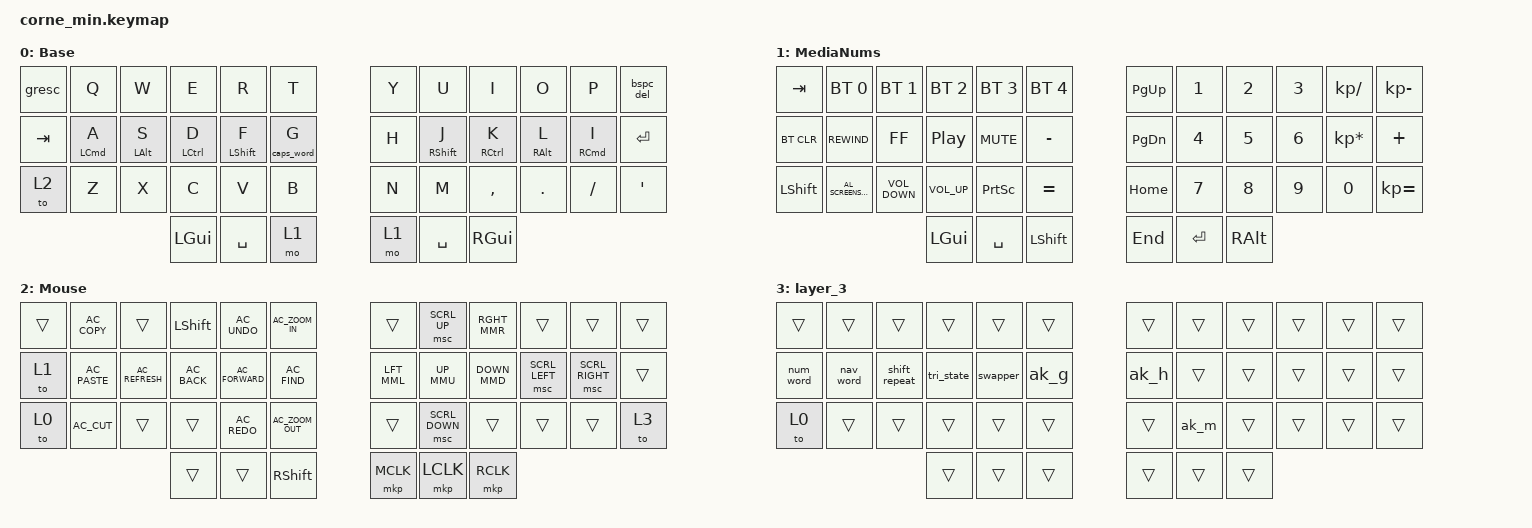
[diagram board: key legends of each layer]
/*
 * Copyright (c) 2020 The ZMK Contributors
 *
 * SPDX-License-Identifier: MIT
 */

#include <behaviors/num_word.dtsi>
#include <behaviors/unicode.dtsi>
#include <zmk-unicode/keys-extra.h>  // All glyphs except CJK
#include <zmk-unicode/keys-full.h>   // All glyphs including CJK
#include <behaviors.dtsi>
#include <dt-bindings/zmk/bt.h>
#include <dt-bindings/zmk/keys.h>
#include <dt-bindings/zmk/pointing.h>

#define DEAD1 F21
#define DEAD2 F22
#define DEAD3 F23
#define DEAD4 F24

/ {
    behaviors {
        bspc_del: bspc_del {
            compatible = "zmk,behavior-mod-morph";
            label = "BSPC_DEL";
            bindings = <&kp BSPC>, <&kp DELETE>;

            #binding-cells = <0>;
            mods = <(MOD_LSFT)>;
        };

        LFT_MML: LFT_MML {
            compatible = "zmk,behavior-mod-morph";
            label = "LFT_MML";
            bindings = <&kp LEFT_ARROW>, <&mmv MOVE_LEFT>;

            #binding-cells = <0>;
            mods = <(MOD_LSFT)>;
        };

        RGHT_MMR: RGHT_MMR {
            compatible = "zmk,behavior-mod-morph";
            label = "RGHT_MMR";
            bindings = <&kp RIGHT_ARROW>, <&mmv MOVE_RIGHT>;

            #binding-cells = <0>;
            mods = <(MOD_LSFT)>;
        };

        UP_MMU: UP_MMU {
            compatible = "zmk,behavior-mod-morph";
            label = "UP_MMU";
            bindings = <&kp UP_ARROW>, <&mmv MOVE_UP>;

            #binding-cells = <0>;
            mods = <(MOD_LSFT)>;
        };

        DOWN_MMD: DOWN_MMD {
            compatible = "zmk,behavior-mod-morph";
            label = "DOWN_MMD";
            bindings = <&kp DOWN_ARROW>, <&mmv MOVE_DOWN>;

            #binding-cells = <0>;
            mods = <(MOD_LSFT)>;
        };

        MAGIC_TAP: MAGIC_TAP {
            compatible = "zmk,behavior-hold-tap";
            label = "MAGIC_TAP";
            bindings = <&kp>, <&kp>;

            #binding-cells = <2>;
            tapping-term-ms = <350>;
            hold-trigger-on-release;
            flavor = "tap-preferred";
            quick-tap-ms = <350>;
            require-prior-idle-ms = <350>;
        };

        HMR_LEFT_TAP: HMR_LEFT_TAP {
            compatible = "zmk,behavior-hold-tap";
            label = "HMR_LEFT_TAP";
            bindings = <&kp>, <&kp>;

            #binding-cells = <2>;
            tapping-term-ms = <350>;
            quick-tap-ms = <350>;
            require-prior-idle-ms = <350>;
            hold-trigger-on-release;
            flavor = "tap-preferred";
            hold-trigger-key-positions = <6 7 8 9 10 11 18 19 20 21 22 23 30 31 32 33 34 35 39 40 41>;
        };

        HMR_RIGHT_TAP: HMR_RIGHT_TAP {
            compatible = "zmk,behavior-hold-tap";
            label = "HMR_RIGHT_TAP";
            bindings = <&kp>, <&kp>;

            #binding-cells = <2>;
            tapping-term-ms = <350>;
            quick-tap-ms = <350>;
            require-prior-idle-ms = <350>;
            hold-trigger-on-release;
            flavor = "tap-preferred";
            hold-trigger-key-positions = <0 1 2 3 4 5 12 13 14 15 16 17 24 25 26 27 28 29 36 37 38>;
        };

        MY_ALLCAPS: MY_ALLCAPS {
            compatible = "zmk,behavior-hold-tap";
            label = "MY_ALLCAPS";
            bindings = <&caps_word>, <&kp>;

            #binding-cells = <2>;
            tapping-term-ms = <350>;
            hold-trigger-on-release;
            flavor = "tap-preferred";
            quick-tap-ms = <350>;
            require-prior-idle-ms = <350>;
            hold-trigger-key-positions = <1 2 3 4 5 13 14 15 16 17 25 26 27 28 29 6 7 8 9 10 18 19 20 21 22 30 31>;
        };

        swapper: swapper {
            compatible = "zmk,behavior-tri-state";
            #binding-cells = <0>;
            bindings = <&kp A>, <&kp B>, <&kt C>;
        };

        tri_state: tri_state {
            compatible = "zmk,behavior-tri-state";
            label = "TRI-STATE";
            #binding-cells = <0>;
            bindings = <&kp A>, <&kp B>, <&kt C>;
        };

        //        leader1: leader1 {
        //            compatible = "zmk,behavior-leader-key";
        //            #binding-cells = <0>;
        //            
        //            ble { sequence = <B L E>; bindings = <&out OUT_BLE>; };
        //            bt0 { sequence = <B N0>; bindings = <&bt BT_SEL 0>; };
        //            bt1 { sequence = <B N1>; bindings = <&bt BT_SEL 1>; };
        //            bt2 { sequence = <B N2>; bindings = <&bt BT_SEL 2>; };
        //            btc { sequence = <C L E A R>; bindings = <&bt BT_CLR>; };
        //            boot { sequence = <B O O T>; bindings = <&bootloader>; };
        //            reset { sequence = <R E S E T>; bindings = <&sys_reset>; };
        //        };
        //
        //        leader2: leader2 {
        //            compatible = "zmk,behavior-leader-key";
        //            #binding-cells = <0>;
        //            
        //	    de_ae { sequence = <A E>; bindings = <&de_ae>; };
        //            de_oe { sequence = <O E>; bindings = <&de_oe>; };
        //            de_ue { sequence = <U E>; bindings = <&de_ue>; };
        //        };

        ak_h: ak_h {
            compatible = "zmk,behavior-adaptive-key";
            #binding-cells = <0>;
            bindings = <&kp H>;

            akt_ah {
                trigger-keys = <A>;
                max-prior-idle-ms = <300>;
                bindings = <&kp U>;
            };

            akt_uh {
                trigger-keys = <U>;
                max-prior-idle-ms = <300>;
                bindings = <&kp A>;
            };

            akt_eh {
                trigger-keys = <E>;
                max-prior-idle-ms = <300>;
                bindings = <&kp O>;
            };
        };

        ak_m: ak_m {
            compatible = "zmk,behavior-adaptive-key";
            #binding-cells = <0>;
            bindings = <&kp M>;

            akt_gm {
                trigger-keys = <G>;
                max-prior-idle-ms = <300>;
                bindings = <&kp L>;
            };

            akt_pm {
                trigger-keys = <P>;
                max-prior-idle-ms = <300>;
                bindings = <&kp L>;
            };
        };

        // And similarly for VP->VL, PV->LV, BT->BL, TB->LB

        ak_g: ak_g {
            compatible = "zmk,behavior-adaptive-key";
            #binding-cells = <0>;
            bindings = <&kp G>;

            // Binding two behaviors: JG->JPG

            akt_jg {
                trigger-keys = <J>;
                max-prior-idle-ms = <300>;
                bindings = <&kp P &kp G>;
            };
        };

        //        ak_e: ak_e {
        //            compatible = "zmk,behavior-adaptive-key";
        //            #binding-cells = <0>;
        //            bindings = <&kp E>;
        //            dead-keys = <GRAVE CARET APOS QUOTE>;
        //
        //            grave { trigger-keys = <GRAVE>; bindings = <&fr_e_grave>; };
        //            acute { trigger-keys = <APOS>; bindings = <&fr_e_acute>; };
        //            circumflex { trigger-keys = <CARET>; bindings = <&fr_e_circumflex>; };
        //            diaeresis { trigger-keys = <QUOTE>; bindings = <&fr_e_diaeresis>; };
        //        };

        shift_repeat: shift_repeat {
            compatible = "zmk,behavior-adaptive-key";
            #binding-cells = <0>;
            bindings = <&sk LSHFT>;

            repeat {
                trigger-keys = <A B C D E F G H I J K L M N O P Q R S T U V W X Y Z>;
                bindings = <&key_repeat>;
                max-prior-idle-ms = <350>;
                strict-modifiers;
            };
        };

        nav_word: nav_word {
            compatible = "zmk,behavior-auto-layer";
            #binding-cells = <1>;
            continue-list = <LEFT DOWN UP RIGHT PG_DN PG_UP>;
            ignore-modifiers;
        };

        num_word: num_word {
            #binding-cells = <0>;
            compatible = "zmk,behavior-num-word";
            continue-list = <BSPC DEL DOT COMMA PLUS MINUS STAR FSLH EQUAL>;
            ignore-numbers;
        };
    };

    combos { compatible = "zmk,combos"; };

    keymap {
        compatible = "zmk,keymap";

        Base_0 {
            display-name = "Base";

            // -----------------------------------------------------------------------------------------
            // |  TAB |  Q  |  W  |  E  |  R  |  T  |   |  Y  |  U   |  I  |  O  |  P  | BSPC |
            // | CTRL |  A  |  S  |  D  |  F  |  G  |   |  H  |  J   |  K  |  L  |  ;  |  '   |
            // | SHFT |  Z  |  X  |  C  |  V  |  B  |   |  N  |  M   |  ,  |  .  |  /  | ESC  |
            //                    | GUI | LWR | SPC |   | ENT | RSE  | ALT |

            bindings = <
&gresc   &kp Q                 &kp W                     &kp E                         &kp R                       &kp T              &kp Y  &kp U                         &kp I                   &kp O                  &kp P                  &bspc_del
&kp TAB  &HMR_LEFT_TAP LCMD A  &HMR_LEFT_TAP LEFT_ALT S  &HMR_LEFT_TAP LEFT_CONTROL D  &HMR_LEFT_TAP LEFT_SHIFT F  &MY_ALLCAPS 0 G    &kp H  &HMR_RIGHT_TAP RIGHT_SHIFT J  &HMR_RIGHT_TAP RCTRL K  &HMR_RIGHT_TAP RALT L  &HMR_RIGHT_TAP RCMD I  &kp RET
&to 2    &kp Z                 &kp X                     &kp C                         &kp V                       &kp B              &kp N  &kp M                         &kp COMMA               &kp DOT                &kp FSLH               &kp SQT
                                                         &kp LEFT_GUI                  &kp SPACE                   &mo 1              &mo 1  &kp SPACE                     &kp RIGHT_GUI
            >;
        };

        MediaNums {
            display-name = "MediaNums";

            // -----------------------------------------------------------------------------------------
            // |  TAB |  1  |  2  |  3  |  4  |  5  |   |  6  |  7  |  8  |  9  |  0  | BSPC |
            // | BTCLR| BT1 | BT2 | BT3 | BT4 | BT5 |   | LFT | DWN |  UP | RGT |     |      |
            // | SHFT |     |     |     |     |     |   |     |     |     |     |     |      |
            //                    | GUI |     | SPC |   | ENT |     | ALT |

            bindings = <
&kp TAB     &bt BT_SEL 0          &bt BT_SEL 1       &bt BT_SEL 2      &bt BT_SEL 3     &bt BT_SEL 4    &kp PG_UP      &kp NUMBER_1  &kp NUMBER_2  &kp NUMBER_3  &kp KP_DIVIDE    &kp KP_SUBTRACT
&bt BT_CLR  &kp C_REWIND          &kp C_FF           &kp C_PLAY_PAUSE  &kp C_MUTE       &kp MINUS       &kp PAGE_DOWN  &kp NUMBER_4  &kp N5        &kp NUMBER_6  &kp KP_MULTIPLY  &kp PLUS
&kp LSHFT   &kp C_AL_SCREENSAVER  &kp C_VOLUME_DOWN  &kp C_VOLUME_UP   &kp PRINTSCREEN  &kp EQUAL       &kp HOME       &kp N7        &kp N8        &kp N9        &kp N0           &kp KP_EQUAL
                                                     &kp LGUI          &kp SPACE        &kp LSHFT       &kp END        &kp RET       &kp RALT
            >;

            label = "MediaNums";
        };

        Mouse {
            bindings = <
&trans  &kp C_AC_COPY   &trans            &kp LSHFT      &kp C_AC_UNDO     &kp C_AC_ZOOM_IN     &trans     &msc SCRL_UP    &RGHT_MMR  &trans          &trans           &trans
&to 1   &kp C_AC_PASTE  &kp C_AC_REFRESH  &kp C_AC_BACK  &kp C_AC_FORWARD  &kp C_AC_FIND        &LFT_MML   &UP_MMU         &DOWN_MMD  &msc SCRL_LEFT  &msc SCRL_RIGHT  &trans
&to 0   &kp C_AC_CUT    &trans            &trans         &kp C_AC_REDO     &kp C_AC_ZOOM_OUT    &trans     &msc SCRL_DOWN  &trans     &trans          &trans           &to 3
                                          &trans         &trans            &kp RSHFT            &mkp MCLK  &mkp LCLK       &mkp RCLK
            >;

            label = "Mouse";
        };

        layer_3 {
            bindings = <
&trans     &trans     &trans         &trans      &trans    &trans    &trans  &trans  &trans  &trans  &trans  &trans
&num_word  &nav_word  &shift_repeat  &tri_state  &swapper  &ak_g     &ak_h   &trans  &trans  &trans  &trans  &trans
&to 0      &trans     &trans         &trans      &trans    &trans    &trans  &ak_m   &trans  &trans  &trans  &trans
                                     &trans      &trans    &trans    &trans  &trans  &trans
            >;
        };
    };

    conditional_layers { compatible = "zmk,conditional-layers"; };
};
